# CC26x0 register map
File version: 2.3
CPU: CM3 r2p1, little endian, no MPU, no FPU, 0x3 interrupt priority bits, 0x0 interrupts
Registers are 32-bit, read-write, reset 0x0 unless marked. A register's access mark holds for its fields unless they carry their own. Offsets are from the block's base; [hi:lo] are bit positions; {n}, {i} and the like mark numbered series.

## RFC_PWR — RF Core Power Management
Base 0x40040000
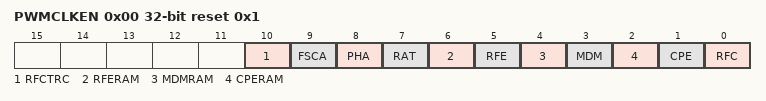
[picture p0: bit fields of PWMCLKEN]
0x00 PWMCLKEN reset 0x1 — RF Core Power Management and Clock Enable
  [10] RFCTRC, [9] FSCA, [8] PHA, [7] RAT, [6] RFERAM, [5] RFE, [4] MDMRAM, [3] MDM, [2] CPERAM, [1] CPE, [0] RFC

## RFC_RAT — RF Core Radio Timer
Base 0x40043000
0x04 RATCNT — Radio Timer Counter Value
  [31:0] CNT
{0x80+4i} RATCH{i}VAL (i=0..7) — Timer Channel {i} Capture/Compare Register
  [31:0] VAL

## SMPH — MCU Semaphore Module This module provides 32 binary semaphores. The state of a binary semaphore is either taken or available. A semaphore does not implement any ownership attribute. Still, a semaphore can be used to handle mutual exclusion scenarios.
Base 0x40084000
{0x0+4i} SMPH{i} reset 0x1 (i=0..31) — MCU SEMAPHORE {i}
  [0] STAT read-clears
{0x800+4i} PEEK{i} ro reset 0x1 (i=0..31) — MCU SEMAPHORE {i} ALIAS
  [0] STAT

## SSI0 — Synchronous Serial Interface with master and slave capabilities
Base 0x40000000
Same registers: SSI1 0x40008000
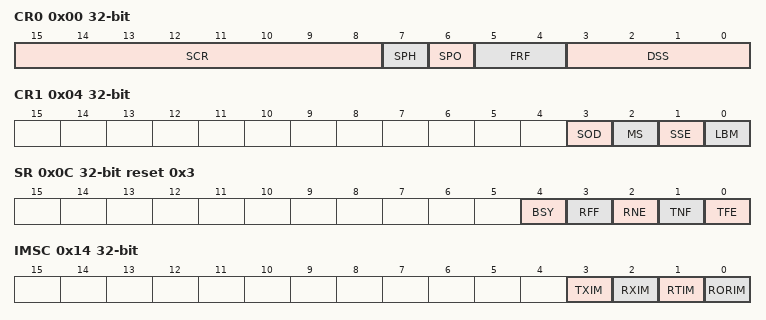
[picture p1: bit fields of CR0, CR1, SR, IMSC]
0x00 CR0 — Control 0
  [15:8] SCR, [7] SPH, [6] SPO, [5:4] FRF, [3:0] DSS
0x04 CR1 — Control 1
  [3] SOD, [2] MS, [1] SSE, [0] LBM
0x08 DR — Data 16-bits wide data register: When read, the entry in the receive FIFO, pointed to by the current FIFO read pointer, is accessed. As data values are removed by the receive logic from the incoming data frame, they are placed into the entry in the receive FIFO, pointed to by the current FIFO write pointer. When written, the entry in the transmit FIFO, pointed to by the write pointer, is written to. Data values are removed from the transmit FIFO one value at a time by the transmit logic. It is loaded into the transmit serial shifter, then serially shifted out onto the TXD output pin at the programmed bit rate. When a data size of less than 16 bits is selected, the user must right-justify data written to the transmit FIFO. The transmit logic ignores the unused bits. Received data less than 16 bits is automatically right-justified in the receive buffer.
  [15:0] DATA
0x0C SR ro reset 0x3 — Status
  [4] BSY, [3] RFF, [2] RNE, [1] TNF, [0] TFE
0x10 CPSR — Clock Prescale
  [7:0] CPSDVSR
0x14 IMSC — Interrupt Mask Set and Clear
  [3] TXIM, [2] RXIM, [1] RTIM, [0] RORIM
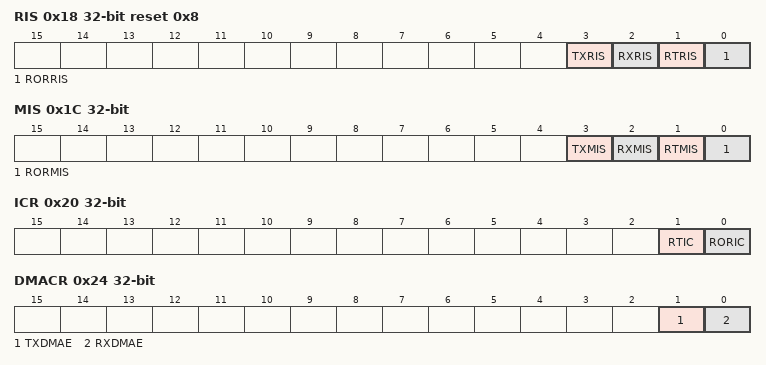
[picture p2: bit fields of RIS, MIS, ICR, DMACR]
0x18 RIS ro reset 0x8 — Raw Interrupt Status
  [3] TXRIS, [2] RXRIS, [1] RTRIS, [0] RORRIS
0x1C MIS ro — Masked Interrupt Status
  [3] TXMIS, [2] RXMIS, [1] RTMIS, [0] RORMIS
0x20 ICR wo — Interrupt Clear On a write of 1, the corresponding interrupt is cleared. A write of 0 has no effect.
  [1] RTIC, [0] RORIC
0x24 DMACR — DMA Control
  [1] TXDMAE, [0] RXDMAE

## TRNG — True Random Number Generator
Base 0x40028000
0x00 OUT0 ro — Random Number Lower Word Readout Value
  [31:0] VALUE_31_0
0x04 OUT1 ro — Random Number Upper Word Readout Value
  [31:0] VALUE_63_32
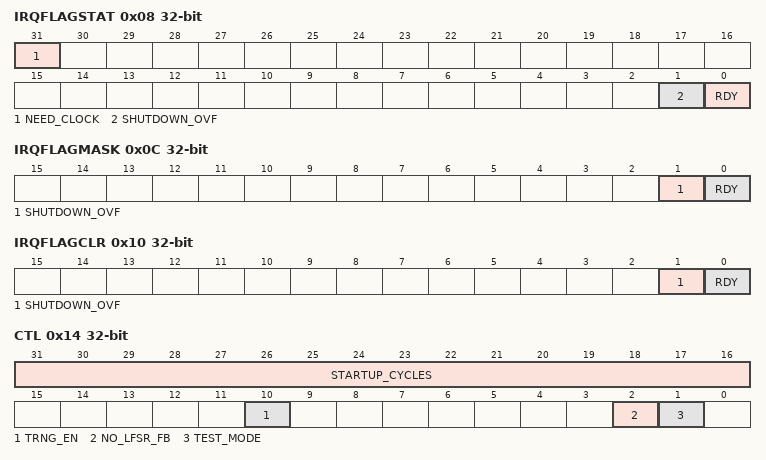
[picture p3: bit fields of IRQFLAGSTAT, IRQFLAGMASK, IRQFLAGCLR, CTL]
0x08 IRQFLAGSTAT ro — Interrupt Status
  [31] NEED_CLOCK, [1] SHUTDOWN_OVF, [0] RDY
0x0C IRQFLAGMASK — Interrupt Mask
  [1] SHUTDOWN_OVF, [0] RDY
0x10 IRQFLAGCLR wo — Interrupt Flag Clear
  [1] SHUTDOWN_OVF, [0] RDY
0x14 CTL — Control
  [31:16] STARTUP_CYCLES, [10] TRNG_EN, [2] NO_LFSR_FB, [1] TEST_MODE
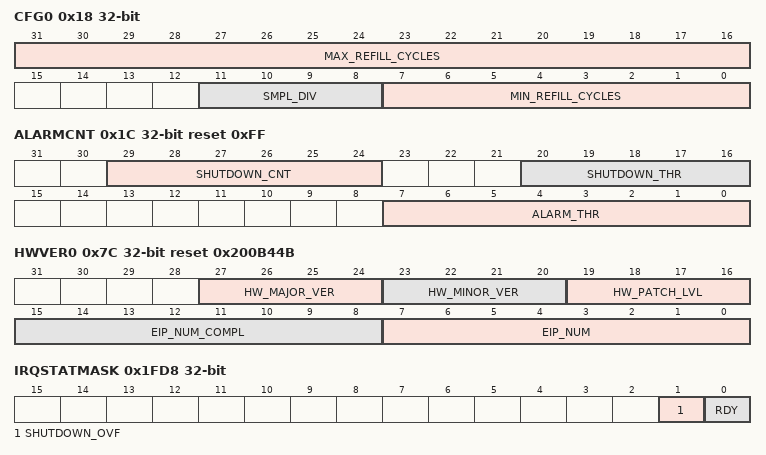
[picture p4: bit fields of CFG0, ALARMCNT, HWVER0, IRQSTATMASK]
0x18 CFG0 — Configuration 0
  [31:16] MAX_REFILL_CYCLES, [11:8] SMPL_DIV, [7:0] MIN_REFILL_CYCLES
0x1C ALARMCNT reset 0xFF — Alarm Control
  [29:24] SHUTDOWN_CNT, [20:16] SHUTDOWN_THR, [7:0] ALARM_THR
0x20 FROEN reset 0xFFFFFF — FRO Enable
  [23:0] FRO_MASK
0x24 FRODETUNE — FRO De-tune Bit
  [23:0] FRO_MASK
0x28 ALARMMASK — Alarm Event
  [23:0] FRO_MASK
0x2C ALARMSTOP — Alarm Shutdown
  [23:0] FRO_FLAGS
0x30 LFSR0 — LFSR Readout Value
  [31:0] LFSR_31_0
0x34 LFSR1 — LFSR Readout Value
  [31:0] LFSR_63_32
0x38 LFSR2 — LFSR Readout Value
  [16:0] LFSR_80_64
0x78 HWOPT ro reset 0x600 — TRNG Engine Options Information
  [11:6] NR_OF_FROS
0x7C HWVER0 ro reset 0x200B44B — HW Version 0 EIP Number And Core Revision
  [27:24] HW_MAJOR_VER, [23:20] HW_MINOR_VER, [19:16] HW_PATCH_LVL, [15:8] EIP_NUM_COMPL, [7:0] EIP_NUM
0x1FD8 IRQSTATMASK ro — Interrupt Status After Masking
  [1] SHUTDOWN_OVF, [0] RDY
0x1FE0 HWVER1 ro reset 0x20 — HW Version 1 TRNG Revision Number
  [7:0] REV
0x1FEC IRQSET — Interrupt Set
0x1FF0 SWRESET — SW Reset Control
  [0] RESET
0x1FF8 IRQSTAT ro — Interrupt Status
  [0] STAT

## UDMA0 — ARM Micro Direct Memory Access Controller
Base 0x40020000
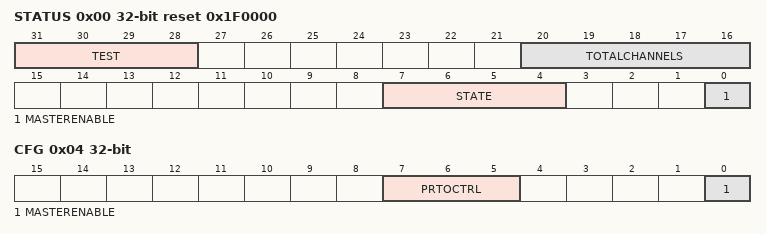
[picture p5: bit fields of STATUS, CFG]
0x00 STATUS ro reset 0x1F0000
  [31:28] TEST, [20:16] TOTALCHANNELS, [7:4] STATE, [0] MASTERENABLE
0x04 CFG wo — Configuration
  [7:5] PRTOCTRL, [0] MASTERENABLE
0x08 CTRL — Channel Control Data Base Pointer
  [31:10] BASEPTR
0x0C ALTCTRL ro reset 0x200 — Channel Alternate Control Data Base Pointer
  [31:0] BASEPTR
0x10 WAITONREQ ro reset 0xFFFF1EFF — Channel Wait On Request Status
  [31:0] CHNLSTATUS
0x14 SOFTREQ wo — Channel Software Request
  [31:0] CHNLS
0x18 SETBURST — Channel Set UseBurst
  [31:0] CHNLS
0x1C CLEARBURST wo — Channel Clear UseBurst
  [31:0] CHNLS
0x20 SETREQMASK — Channel Set Request Mask
  [31:0] CHNLS
0x24 CLEARREQMASK wo — Clear Channel Request Mask
  [31:0] CHNLS
0x28 SETCHANNELEN — Set Channel Enable
  [31:0] CHNLS
0x2C CLEARCHANNELEN wo — Clear Channel Enable
  [31:0] CHNLS
0x30 SETCHNLPRIALT — Channel Set Primary-Alternate
  [31:0] CHNLS
0x34 CLEARCHNLPRIALT wo — Channel Clear Primary-Alternate
  [31:0] CHNLS
0x38 SETCHNLPRIORITY — Set Channel Priority
  [31:0] CHNLS
0x3C CLEARCHNLPRIORITY wo — Clear Channel Priority
  [31:0] CHNLS
0x4C ERROR — Error Status and Clear
  [0] STATUS
0x504 REQDONE — Channel Request Done
  [31:0] CHNLS
0x520 DONEMASK — Channel Request Done Mask
  [31:0] CHNLS

## VIMS — Versatile Instruction Memory System Controls memory access to the Flash and encapsulates the following instruction memories: - Boot ROM - Cache / GPRAM
Base 0x40034000
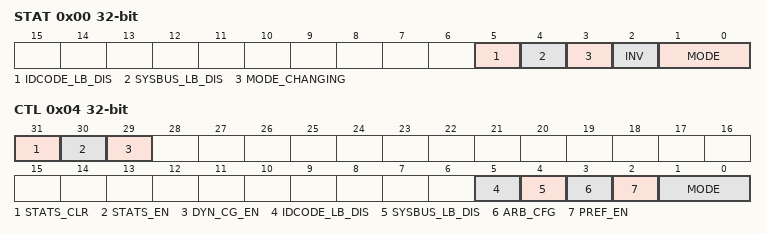
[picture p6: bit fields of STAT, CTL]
0x00 STAT ro — Status Displays current VIMS mode and line buffer status
  [5] IDCODE_LB_DIS, [4] SYSBUS_LB_DIS, [3] MODE_CHANGING, [2] INV, [1:0] MODE
0x04 CTL — Control Configure VIMS mode and line buffer settings
  [31] STATS_CLR, [30] STATS_EN, [29] DYN_CG_EN, [5] IDCODE_LB_DIS, [4] SYSBUS_LB_DIS, [3] ARB_CFG, [2] PREF_EN, [1:0] MODE

## WDT — Watchdog Timer
Base 0x40080000
0x00 LOAD reset 0xFFFFFFFF — Configuration
  [31:0] WDTLOAD
0x04 VALUE ro reset 0xFFFFFFFF — Current Count Value
  [31:0] WDTVALUE
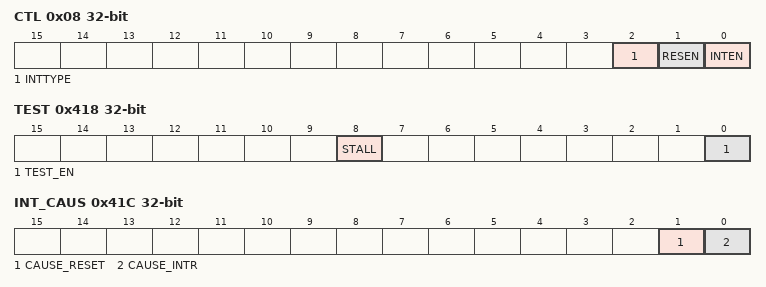
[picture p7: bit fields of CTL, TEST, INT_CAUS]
0x08 CTL — Control
  [2] INTTYPE, [1] RESEN, [0] INTEN
0x0C ICR wo — Interrupt Clear
  [31:0] WDTICR
0x10 RIS ro — Raw Interrupt Status
  [0] WDTRIS
0x14 MIS ro — Masked Interrupt Status
  [0] WDTMIS
0x418 TEST — Test Mode
  [8] STALL, [0] TEST_EN
0x41C INT_CAUS ro — Interrupt Cause Test Mode
  [1] CAUSE_RESET, [0] CAUSE_INTR
0xC00 LOCK
  [31:0] WDTLOCK
